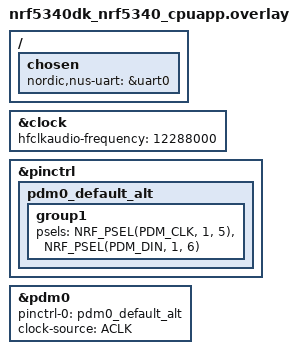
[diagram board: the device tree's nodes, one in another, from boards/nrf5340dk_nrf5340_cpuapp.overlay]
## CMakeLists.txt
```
cmake_minimum_required(VERSION 3.13.1)

find_package(Zephyr REQUIRED HINTS $ENV{ZEPHYR_BASE})
project(ble_to_cloud_from_scratch)

# NORDIC SDK APP START
target_sources(app PRIVATE src/main.c)
# NORDIC SDK APP END

# Include source directory
target_include_directories(app PRIVATE src/include)
```

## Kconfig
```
#
# Copyright (c) 2018 Nordic Semiconductor
#
# SPDX-License-Identifier: LicenseRef-Nordic-5-Clause
#

source "Kconfig.zephyr"

menu "Nordic UART BLE GATT service sample"

# config BT_NUS_THREAD_STACK_SIZE
# 	int "Thread stack size"
# 	default 1024
# 	help
# 	  Stack size used in each of the two threads

# config BT_NUS_UART_BUFFER_SIZE
# 	int "UART payload buffer element size"
# 	default 40
# 	help
# 	  Size of the payload buffer in each RX and TX FIFO element

# config BT_NUS_SECURITY_ENABLED
# 	bool "Enable security"
# 	default y
# 	select BT_SMP
# 	help
# 	  "Enable BLE security for the UART service"

# config BT_NUS_UART_RX_WAIT_TIME
# 	int "Timeout for UART RX complete event"
# 	default 50
# 	help
# 	  Wait for RX complete event time in milliseconds

# config BT_NUS_UART_ASYNC_ADAPTER
# 	bool "Enable UART async adapter"
# 	select SERIAL_SUPPORT_ASYNC
# 	help
# 	  Enables asynchronous adapter for UART drives that supports only
# 	  IRQ interface.

endmenu
```

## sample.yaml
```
sample:
  description: Sample showing Edge Impulse wrapper usage
  name: Edge Impulse wrapper sample using sound
tests:
  sample.bluetooth.central_uart:
    build_only: true
    integration_platforms:
      - nrf5340dk_nrf5340_cpuapp
      - nrf5340dk_nrf5340_cpuapp_ns
      - nrf52840dk_nrf52840
    platform_allow: 
      nrf5340dk_nrf5340_cpuapp nrf5340dk_nrf5340_cpuapp_ns nrf52840dk_nrf52840


    
```

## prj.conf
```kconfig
#
# Copyright (c) 2021 Nordic Semiconductor ASA
#
# SPDX-License-Identifier: LicenseRef-Nordic-5-Clause

#Flash
CONFIG_FLASH=y
CONFIG_FLASH_PAGE_LAYOUT=y
CONFIG_FLASH_MAP=y
CONFIG_NVS=y
CONFIG_SETTINGS=y

CONFIG_ASSERT=y

# Logging
CONFIG_RTT_CONSOLE=y
CONFIG_LOG=y
CONFIG_LOG_BACKEND_RTT=y
CONFIG_USE_SEGGER_RTT=y
CONFIG_LOG_BACKEND_UART=n

# Enable Edge Impulse dependencies
CONFIG_CPLUSPLUS=y
CONFIG_STD_CPP11=y
CONFIG_LIB_CPLUSPLUS=y
CONFIG_NEWLIB_LIBC=y
CONFIG_NEWLIB_LIBC_FLOAT_PRINTF=y
CONFIG_FP16=n

# Enable Edge Impulse
CONFIG_EDGE_IMPULSE=y
CONFIG_EDGE_IMPULSE_URI="woodpeckerdetector-v30.zip"
CONFIG_EI_WRAPPER=y
CONFIG_EI_WRAPPER_DATA_BUF_SIZE=19000
CONFIG_RESET_ON_FATAL_ERROR=n
CONFIG_BT_HCI=y

# This example requires more workqueue stack
CONFIG_SYSTEM_WORKQUEUE_STACK_SIZE=4096
CONFIG_HEAP_MEM_POOL_SIZE=8192
CONFIG_MAIN_STACK_SIZE=2048

#Dmic enable
CONFIG_AUDIO=y
CONFIG_AUDIO_DMIC=y


# Enable DK LED and Buttons library
CONFIG_DK_LIBRARY=y
```

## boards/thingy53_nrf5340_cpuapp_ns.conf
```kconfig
#
# Copyright (c) 2021 Nordic Semiconductor ASA
#
# SPDX-License-Identifier: LicenseRef-Nordic-5-Clause
#
################################################################################
# Application overlay - Thingy:53 DFU

CONFIG_MCUMGR=y
CONFIG_MCUMGR_SMP_BT=y
CONFIG_MCUMGR_SMP_BT_AUTHEN=n
CONFIG_MCUMGR_SMP_BT_CONN_PARAM_CONTROL=y

CONFIG_MCUMGR_CMD_IMG_MGMT=y
CONFIG_MCUMGR_CMD_OS_MGMT=y

# Enable custom SMP request to erase settings partition.
CONFIG_MCUMGR_GRP_ZEPHYR_BASIC=y
CONFIG_MCUMGR_GRP_BASIC_CMD_STORAGE_ERASE=y



CONFIG_BT_L2CAP_TX_MTU=498
CONFIG_BT_BUF_ACL_TX_SIZE=251
CONFIG_BT_BUF_ACL_RX_SIZE=502

# Use connection parameters that ensure quick data transfer
CONFIG_BT_PERIPHERAL_PREF_MIN_INT=6
CONFIG_BT_PERIPHERAL_PREF_MAX_INT=6
CONFIG_BT_PERIPHERAL_PREF_LATENCY=99
CONFIG_BT_PERIPHERAL_PREF_TIMEOUT=400

################################################################################
# Bootloader configuration

CONFIG_BOOTLOADER_MCUBOOT=y
CONFIG_MCUBOOT_IMAGE_VERSION="1.0.0+0"
CONFIG_UPDATEABLE_IMAGE_NUMBER=2

CONFIG_IMG_MANAGER=y
CONFIG_MCUBOOT_IMG_MANAGER=y
CONFIG_IMG_ERASE_PROGRESSIVELY=y

################################################################################
# External flash configuration

CONFIG_NORDIC_QSPI_NOR=y
CONFIG_NORDIC_QSPI_NOR_FLASH_LAYOUT_PAGE_SIZE=4096
CONFIG_NORDIC_QSPI_NOR_STACK_WRITE_BUFFER_SIZE=16

# FLASH nop device is enabled to prevent bus faults when mcumgr tries to access
# simulated partition with network core image data.
CONFIG_FLASH_NOP_DEVICE=y

################################################################################
# Enable USB CDC ACM

CONFIG_USB_DEVICE_STACK=y
CONFIG_USB_DEVICE_REMOTE_WAKEUP=n
CONFIG_USB_DEVICE_PRODUCT="Thingy:53 Nordic UART Service sample"
CONFIG_USB_DEVICE_VID=0x1915
CONFIG_USB_DEVICE_PID=0x530E
CONFIG_USB_COMPOSITE_DEVICE=y
CONFIG_USB_CDC_ACM=y
CONFIG_USB_CDC_ACM_LOG_LEVEL_ERR=y
CONFIG_USB_DEVICE_LOG_LEVEL_ERR=y

CONFIG_LOG_BACKEND_UART=y
CONFIG_LOG_PRINTK=y
CONFIG_LOG_PROCESS_THREAD_STACK_SIZE=1024
CONFIG_LOG_PROCESS_THREAD_STARTUP_DELAY_MS=4000


CONFIG_BOOTLOADER_MCUBOOT=y


#SPM

CONFIG_BUILD_WITH_TFM=n
CONFIG_SPM=y

#Flash
CONFIG_FLASH=y
CONFIG_FLASH_PAGE_LAYOUT=y
CONFIG_FLASH_MAP=y
CONFIG_NVS=y
CONFIG_SETTINGS=y

# Enable DK LED and Buttons library
CONFIG_DK_LIBRARY=y



# Config logger
CONFIG_LOG=y
CONFIG_USE_SEGGER_RTT=y
CONFIG_LOG_BACKEND_RTT=y
CONFIG_LOG_BACKEND_UART=n

CONFIG_ASSERT=y
```

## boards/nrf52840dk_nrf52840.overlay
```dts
/*
 * Copyright (c) 2022 Nordic Semiconductor ASA
 *
 * SPDX-License-Identifier: LicenseRef-Nordic-5-Clause
 */



 &pinctrl {
	pdm0_default_alt: pdm0_default_alt {
		group1 {
			psels = <NRF_PSEL(PDM_CLK, 1, 4)>,
				<NRF_PSEL(PDM_DIN, 1, 5)>;
		};
	};
};

dmic_dev: &pdm0 {
	status = "okay";
	pinctrl-0 = <&pdm0_default_alt>;
	pinctrl-names = "default";
	clock-source = "PCLK32M_HFXO";
	
};
```

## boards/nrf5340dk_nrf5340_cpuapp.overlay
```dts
/*
 * Copyright (c) 2022 Nordic Semiconductor ASA
 *
 * SPDX-License-Identifier: LicenseRef-Nordic-5-Clause
 */

/ {
	chosen {
		nordic,nus-uart = &uart0;
        
	};
};

 &clock {
    hfclkaudio-frequency = <12288000>;
};
&pinctrl {
    pdm0_default_alt: pdm0_default_alt {
        group1 {
            psels = <NRF_PSEL(PDM_CLK, 1, 5)>,
                <NRF_PSEL(PDM_DIN, 1, 6)>;
        };
    };
};
dmic_dev: &pdm0 {
    status = "okay";
    pinctrl-0 = <&pdm0_default_alt>;
    pinctrl-names = "default";
    clock-source = "ACLK";
};
```

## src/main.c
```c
/*
 * Copyright (c) 2021 Nordic Semiconductor ASA
 *
 * SPDX-License-Identifier: LicenseRef-Nordic-5-Clause
 */

#include <mic.h>

LOG_MODULE_REGISTER(MAIN);

/* Edge Impulse results ready. */
static void result_ready_cb(int err)
{
	if(err){
		LOG_INF("Result ready callback error: %d", err);
		return;
	}

	const char *label;
	float value;
	size_t inx;

	while(true){
		err = ei_wrapper_get_next_classification_result(&label, &value, &inx);

		if(err){
			LOG_INF("Unable to get next classification result: %d", err);
			break;
		}
		if(inx == 2){

			LOG_INF("Woodpecker probabilaty: %f", value);
			break;
            
		}
	}
	if(!err){
		if(ei_wrapper_classifier_has_anomaly()){
			float anomaly;
			err = ei_wrapper_get_anomaly(&anomaly);
		}
	}

	bool cancelled;
	err = ei_wrapper_clear_data(&cancelled);
	if(err){
		LOG_INF("Unable to clear data: %i", err);
	}
}


static int do_pdm_transfer(const struct device *dmic_dev,
			   struct dmic_cfg *cfg,
			   size_t block_count)
{
	int ret;

	LOG_INF("Starting sampling:");

	/* Start the microphone. */
	ret = dmic_trigger(dmic_dev, DMIC_TRIGGER_START);
	if (ret < 0) {
		LOG_INF("START trigger failed: %d", ret);
		return ret;
	}
	
	for (int i = 0; i < 11; ++i) {
		void *buffer;
		uint32_t size;

		ret = dmic_read(dmic_dev, 0, &buffer, &size, READ_TIMEOUT);
		if (ret < 0) {
			LOG_INF("Read failed: %d", ret);
			break;
		}

		/* Discard first readout due to microphone needing to 
		 * stabilize before valid data can be read. */
		if(i!=0){
			int16_t tempInt;
			float tempFloat;
			for(int j=0; j<1600; j++){
				memcpy(&tempInt, buffer + 2*j, 2);
				tempFloat = (float)tempInt;
				audio[(i-1)*1600+j] = tempFloat;
			}
		}
		k_mem_slab_free(&mem_slab, &buffer);
	}

	/* Stop the microphone. */
	ret = dmic_trigger(dmic_dev, DMIC_TRIGGER_STOP);
	if (ret < 0) {
		return ret;
	}

	/* Give the microphone data to Edge Impulse. */
	ret = ei_wrapper_add_data(&audio, ei_wrapper_get_window_size());
	if (ret) {
		LOG_INF("Cannot provide input data (err: %d)\n", ret);
		LOG_INF("Increase CONFIG_EI_WRAPPER_DATA_BUF_SIZE\n");
	}
	ei_wrapper_start_prediction(0,0);

	return 0;
}




	



	void main()
	{
	int ret;
	ret = ei_wrapper_init(result_ready_cb);

	if(ret){
		LOG_ERR("EI wrapper failed to init: %i", ret);
	}
   
	
    k_sleep(K_SECONDS(15));
	
	const struct device *dmic_dev = DEVICE_DT_GET(DT_NODELABEL(dmic_dev));

	LOG_INF("DMIC module");

	if (!device_is_ready(dmic_dev)) {
		LOG_ERR("%s is not ready", dmic_dev->name);
		return;
	}

	/* Configuration of the microphone. */
	struct pcm_stream_cfg stream = {
		.pcm_width = SAMPLE_BIT_WIDTH,
		.mem_slab  = &mem_slab,
	};
	struct dmic_cfg cfg = {
		.io = {
			/* These fields can be used to limit the PDM clock
			 * configurations that the driver is allowed to use
			 * to those supported by the microphone.
			 */
			.min_pdm_clk_freq = 1100000,
			.max_pdm_clk_freq = 3500000,
			.min_pdm_clk_dc   = 40,
			.max_pdm_clk_dc   = 60,
		},
		.streams = &stream,
		.channel = {
			.req_num_streams = 1,
		},
	};

	cfg.channel.req_num_chan = 1;
	cfg.channel.req_chan_map_lo =
		dmic_build_channel_map(0, 0, PDM_CHAN_LEFT);
	cfg.streams[0].pcm_rate = MAX_SAMPLE_RATE;
	cfg.streams[0].block_size =
		BLOCK_SIZE(cfg.streams[0].pcm_rate, cfg.channel.req_num_chan);


	cfg.channel.req_num_chan = 2;
	cfg.channel.req_chan_map_lo =
		dmic_build_channel_map(0, 0, PDM_CHAN_LEFT) |
		dmic_build_channel_map(1, 0, PDM_CHAN_RIGHT);
	cfg.streams[0].pcm_rate = MAX_SAMPLE_RATE;
	cfg.streams[0].block_size =
		BLOCK_SIZE(cfg.streams[0].pcm_rate, cfg.channel.req_num_chan);

	ret = dmic_configure(dmic_dev, &cfg);
	if (ret < 0) {
		return;
	}


	while(true){


			ret = do_pdm_transfer(dmic_dev, &cfg, 2 * BLOCK_COUNT);
			if (ret < 0) {
				return;
			k_sleep(K_SECONDS(15));
		 }
			k_sleep(K_SECONDS(1));
	}
	}
	
```
